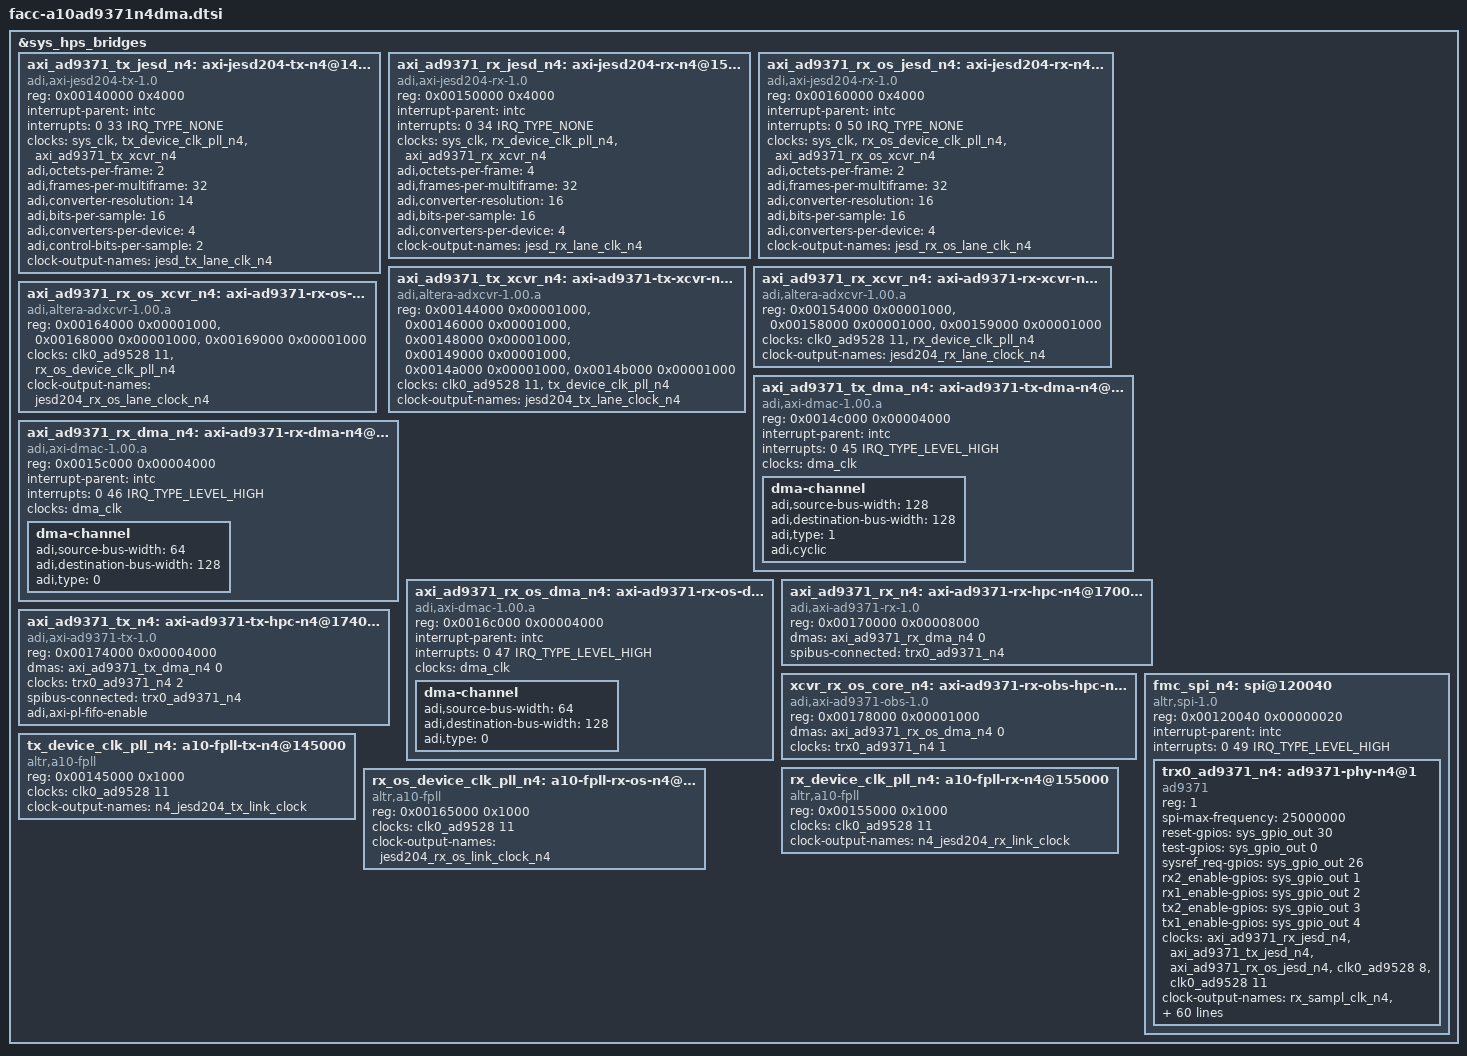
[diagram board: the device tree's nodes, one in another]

&sys_hps_bridges {
	axi_ad9371_tx_jesd_n4: axi-jesd204-tx-n4@140000 {
		compatible = "adi,axi-jesd204-tx-1.0";
		reg = <0x00140000 0x4000>;

		interrupt-parent = <&intc>;
		interrupts = <0 33 IRQ_TYPE_NONE>;

		clocks = <&sys_clk>, <&tx_device_clk_pll_n4>, <&axi_ad9371_tx_xcvr_n4>;
		clock-names = "s_axi_aclk", "device_clk", "lane_clk";

		adi,octets-per-frame = <2>;
		adi,frames-per-multiframe = <32>;
		adi,converter-resolution = <14>;
		adi,bits-per-sample = <16>;
		adi,converters-per-device = <4>;
		adi,control-bits-per-sample = <2>;

		#clock-cells = <0>;
		clock-output-names = "jesd_tx_lane_clk_n4";
	};

	axi_ad9371_rx_jesd_n4: axi-jesd204-rx-n4@150000 {
		compatible = "adi,axi-jesd204-rx-1.0";
		reg = <0x00150000 0x4000>;

		interrupt-parent = <&intc>;
		interrupts = <0 34 IRQ_TYPE_NONE>;

		clocks = <&sys_clk>, <&rx_device_clk_pll_n4>, <&axi_ad9371_rx_xcvr_n4>;
		clock-names = "s_axi_aclk", "device_clk", "lane_clk";

		adi,octets-per-frame = <4>;
		adi,frames-per-multiframe = <32>;
		adi,converter-resolution = <16>;
		adi,bits-per-sample = <16>;
		adi,converters-per-device = <4>;

		#clock-cells = <0>;
		clock-output-names = "jesd_rx_lane_clk_n4";
	};

	axi_ad9371_rx_os_jesd_n4: axi-jesd204-rx-n4@160000 {
		compatible = "adi,axi-jesd204-rx-1.0";
		reg = <0x00160000 0x4000>;

		interrupt-parent = <&intc>;
		interrupts = <0 50 IRQ_TYPE_NONE>;

		clocks = <&sys_clk>, <&rx_os_device_clk_pll_n4>, <&axi_ad9371_rx_os_xcvr_n4>;
		clock-names = "s_axi_aclk", "device_clk", "lane_clk";

		adi,octets-per-frame = <2>;
		adi,frames-per-multiframe = <32>;
		adi,converter-resolution = <16>;
		adi,bits-per-sample = <16>;
		adi,converters-per-device = <4>;

		#clock-cells = <0>;
		clock-output-names = "jesd_rx_os_lane_clk_n4";
	};

	 axi_ad9371_tx_xcvr_n4: axi-ad9371-tx-xcvr-n4@144000 {
		compatible = "adi,altera-adxcvr-1.00.a";
		reg = <0x00144000 0x00001000>,
			<0x00146000 0x00001000>,
			<0x00148000 0x00001000>,
			<0x00149000 0x00001000>,
			<0x0014a000 0x00001000>,
			<0x0014b000 0x00001000>;
		reg-names = "adxcvr", "atx-pll", "adxcfg-0", "adxcfg-1", "adxcfg-2", "adxcfg-3";

		clocks = <&clk0_ad9528 11>, <&tx_device_clk_pll_n4>;
		clock-names = "ref", "link";

		#clock-cells = <0>;
		clock-output-names = "jesd204_tx_lane_clock_n4";
	};

	axi_ad9371_rx_xcvr_n4: axi-ad9371-rx-xcvr-n4@154000 {
		compatible = "adi,altera-adxcvr-1.00.a";
		reg = <0x00154000 0x00001000>,
			<0x00158000 0x00001000>,
			<0x00159000 0x00001000>;
		reg-names = "adxcvr", "adxcfg-0", "adxcfg-1";

		clocks = <&clk0_ad9528 11>, <&rx_device_clk_pll_n4>;
		clock-names = "ref", "link";

		#clock-cells = <0>;
		clock-output-names = "jesd204_rx_lane_clock_n4";
	};

	axi_ad9371_rx_os_xcvr_n4: axi-ad9371-rx-os-xcvr-n4@164000 {
		compatible = "adi,altera-adxcvr-1.00.a";
		reg = <0x00164000 0x00001000>,
			<0x00168000 0x00001000>,
			<0x00169000 0x00001000>;
		reg-names = "adxcvr", "adxcfg-0", "adxcfg-1";

		clocks = <&clk0_ad9528 11>, <&rx_os_device_clk_pll_n4>;
		clock-names = "ref", "link";

		#clock-cells = <0>;
		clock-output-names = "jesd204_rx_os_lane_clock_n4";
	};

	axi_ad9371_tx_dma_n4: axi-ad9371-tx-dma-n4@14c000 {
		compatible = "adi,axi-dmac-1.00.a";
		reg = <0x0014c000 0x00004000>;
		interrupt-parent = <&intc>;
		interrupts = <0 45 IRQ_TYPE_LEVEL_HIGH>;
		#dma-cells = <1>;
		clocks = <&dma_clk>;

		dma-channel {
			adi,source-bus-width = <128>;
			adi,destination-bus-width = <128>;
			adi,type = <1>;
			adi,cyclic;
		};
	};

	axi_ad9371_rx_dma_n4: axi-ad9371-rx-dma-n4@15c000 {
		compatible = "adi,axi-dmac-1.00.a";
		reg = <0x0015c000 0x00004000>;
		interrupt-parent = <&intc>;
		interrupts = <0 46 IRQ_TYPE_LEVEL_HIGH>;
		#dma-cells = <1>;
		clocks = <&dma_clk>;

		dma-channel {
			adi,source-bus-width = <64>;
			adi,destination-bus-width = <128>;
			adi,type = <0>;
		};
	};

	axi_ad9371_rx_os_dma_n4: axi-ad9371-rx-os-dma-n4@16c000 {
		compatible = "adi,axi-dmac-1.00.a";
		reg = <0x0016c000 0x00004000>;
		interrupt-parent = <&intc>;
		interrupts = <0 47 IRQ_TYPE_LEVEL_HIGH>;
		#dma-cells = <1>;
		clocks = <&dma_clk>;

		dma-channel {
			adi,source-bus-width = <64>;
			adi,destination-bus-width = <128>;
			adi,type = <0>;
		};
	};

	axi_ad9371_rx_n4: axi-ad9371-rx-hpc-n4@170000 {
		compatible = "adi,axi-ad9371-rx-1.0";
		reg = <0x00170000 0x00008000>;
		dmas = <&axi_ad9371_rx_dma_n4 0>;
		dma-names = "rx";
		spibus-connected = <&trx0_ad9371_n4>;
	};

	axi_ad9371_tx_n4: axi-ad9371-tx-hpc-n4@174000 {
		compatible = "adi,axi-ad9371-tx-1.0";
		reg = <0x00174000 0x00004000>;
		dmas = <&axi_ad9371_tx_dma_n4 0>;
		dma-names = "tx";
		clocks = <&trx0_ad9371_n4 2>;
		clock-names = "sampl_clk";
		spibus-connected = <&trx0_ad9371_n4>;
		adi,axi-pl-fifo-enable;/* RxDMA fifo mode */
		//adi,axi-pl-fifo-disable;
	};

	xcvr_rx_os_core_n4: axi-ad9371-rx-obs-hpc-n4@178000 {
		compatible = "adi,axi-ad9371-obs-1.0";
		reg = <0x00178000 0x00001000>;
		dmas = <&axi_ad9371_rx_os_dma_n4 0>;
		dma-names = "rx";
		clocks = <&trx0_ad9371_n4 1>;
		clock-names = "sampl_clk";
	};

	tx_device_clk_pll_n4: a10-fpll-tx-n4@145000 {
		compatible = "altr,a10-fpll";
		reg = <0x00145000 0x1000>;
		clocks = <&clk0_ad9528 11>;

		#clock-cells = <0>;
		clock-output-names = "n4_jesd204_tx_link_clock";
	};

	rx_device_clk_pll_n4: a10-fpll-rx-n4@155000 {
		compatible = "altr,a10-fpll";
		reg = <0x00155000 0x1000>;
		clocks = <&clk0_ad9528 11>;

		#clock-cells = <0>;
		clock-output-names = "n4_jesd204_rx_link_clock";
	};

	rx_os_device_clk_pll_n4: a10-fpll-rx-os-n4@165000 {
		compatible = "altr,a10-fpll";
		reg = <0x00165000 0x1000>;
		clocks = <&clk0_ad9528 11>;

		#clock-cells = <0>;
		clock-output-names = "jesd204_rx_os_link_clock_n4";
	};

	fmc_spi_n4: spi@120040 {
		compatible = "altr,spi-1.0";
		reg = <0x00120040 0x00000020>;
		interrupt-parent = <&intc>;
		interrupts = <0 49 IRQ_TYPE_LEVEL_HIGH>;
		#address-cells = <0x1>;
		#size-cells = <0x0>;
	};
};

&fmc_spi_n4 {
	trx0_ad9371_n4: ad9371-phy-n4@1 {
		#address-cells = <1>;
		#size-cells = <0>;
		#clock-cells = <1>;
		compatible = "ad9371";

		/* SPI Setup */
		reg = <1>;
		spi-max-frequency = <25000000>;

		reset-gpios = <&sys_gpio_out 30 0>;
		test-gpios = <&sys_gpio_out 0 0>;
		sysref_req-gpios = <&sys_gpio_out 26 0>;
		rx2_enable-gpios = <&sys_gpio_out 1 0>;
		rx1_enable-gpios = <&sys_gpio_out 2 0>;
		tx2_enable-gpios = <&sys_gpio_out 3 0>;
		tx1_enable-gpios = <&sys_gpio_out 4 0>;

		/* all interrupts in HW design should be reviewed */
		//interrupt-parent = <&intc>;
		//interrupts = <0 49 IRQ_TYPE_LEVEL_HIGH>;

		/* Clocks */
		clocks = <&axi_ad9371_rx_jesd_n4>, <&axi_ad9371_tx_jesd_n4>,
			<&axi_ad9371_rx_os_jesd_n4>, <&clk0_ad9528 8>,
			<&clk0_ad9528 11>;
		clock-names = "jesd_rx_clk", "jesd_tx_clk",
			"jesd_rx_os_clk", "dev_clk", "fmc_clk";
		clock-output-names = "rx_sampl_clk_n4", "rx_os_sampl_clk_n4", "tx_sampl_clk_n4";

		adi,clocks-clk-pll-vco-freq_khz = <9830400>;
		adi,clocks-device-clock_khz = <122880>;
		adi,clocks-clk-pll-hs-div = <4>;
		adi,clocks-clk-pll-vco-div = <2>;

		adi,jesd204-obs-framer-over-sample = <0>;

		adi,rx-profile-adc-div = <1>;
		adi,rx-profile-en-high-rej-dec5 = <1>;
		adi,rx-profile-iq-rate_khz = <122880>;
		adi,rx-profile-rf-bandwidth_hz = <100000000>;
		adi,rx-profile-rhb1-decimation = <1>;
		adi,rx-profile-rx-bbf-3db-corner_khz = <100000>;
		adi,rx-profile-rx-dec5-decimation = <5>;
		adi,rx-profile-rx-fir-decimation = <2>;

		adi,rx-profile-rx-fir-gain_db = <(-6)>;
		adi,rx-profile-rx-fir-num-fir-coefs = <48>;
		adi,rx-profile-rx-fir-coefs = /bits/ 16 <(-5) (-26) (32) (51) (-67) (-116) (140) (212) (-252) (-367) (429) (595) (-688) (-931) (1072) (1427) (-1650) (-2188) (2612) (3496) (-4802) (-7591) (9656) (32317) (32317) (9656) (-7591) (-4802) (3496) (2612) (-2188) (-1650) (1427) (1072) (-931) (-688) (595) (429) (-367) (-252) (212) (140) (-116) (-67) (51) (32) (-26) (-5)>;

		adi,rx-profile-custom-adc-profile = /bits/ 16  <534 386 201 98 1280 491 1591 279 1306 104 792 28 48 39 23 187>;

		adi,obs-profile-adc-div = <1>;
		adi,obs-profile-en-high-rej-dec5 = <1>;
		adi,obs-profile-iq-rate_khz = <245760>;
		adi,obs-profile-rf-bandwidth_hz = <200000000>;
		adi,obs-profile-rhb1-decimation = <1>;
		adi,obs-profile-rx-bbf-3db-corner_khz = <100000>;
		adi,obs-profile-rx-dec5-decimation = <5>;
		adi,obs-profile-rx-fir-decimation = <1>;

		adi,obs-profile-rx-fir-gain_db = <6>;
		adi,obs-profile-rx-fir-num-fir-coefs = <24>;
		adi,obs-profile-rx-fir-coefs = /bits/ 16 <(-289) (81) (-23) (-86) (229) (-354) (397) (-233) (-657) (1699) (-4172) (23010) (-4172) (1699) (-657) (-233) (397) (-354) (229) (-86) (-23) (81) (-289) (0)>;

		adi,obs-profile-custom-adc-profile = /bits/ 16  <450 349 201 98 1280 730 1626 818 1476 732 834 20 41 36 24 200>;
		adi,obs-settings-custom-loopback-adc-profile = /bits/ 16  <569 369 201 98 1280 291 1541 149 1320 58 807 34 48 40 23 189>;

		adi,tx-profile-dac-div = <1>;
		adi,tx-profile-iq-rate_khz = <245760>;
		adi,tx-profile-primary-sig-bandwidth_hz = <75000000>;
		adi,tx-profile-rf-bandwidth_hz = <200000000>;
		adi,tx-profile-thb1-interpolation = <2>;
		adi,tx-profile-thb2-interpolation = <1>;
		adi,tx-profile-tx-bbf-3db-corner_khz = <100000>;
		adi,tx-profile-tx-dac-3db-corner_khz = <187000>;
		adi,tx-profile-tx-fir-interpolation = <1>;
		adi,tx-profile-tx-input-hb-interpolation = <1>;

		adi,tx-profile-tx-fir-gain_db = <6>;
		adi,tx-profile-tx-fir-num-fir-coefs = <16>;
		adi,tx-profile-tx-fir-coefs = /bits/ 16 <(6) (-270) (203) (-168) (-84) (983) (-3222) (21143) (-3222) (983) (-84) (-168) (203) (-270) (6) (0)>;

		adi,sniffer-profile-adc-div = <1>;
		adi,sniffer-profile-en-high-rej-dec5 = <0>;
		adi,sniffer-profile-iq-rate_khz = <30720>;
		adi,sniffer-profile-rf-bandwidth_hz = <20000000>;
		adi,sniffer-profile-rhb1-decimation = <2>;
		adi,sniffer-profile-rx-bbf-3db-corner_khz = <100000>;
		adi,sniffer-profile-rx-dec5-decimation = <5>;
		adi,sniffer-profile-rx-fir-decimation = <4>;
#if 0
		/* Jacky:2018/07/25: enable pin-mode 
		   https://wiki.analog.com/resources/tools-software/linux-drivers/iio-transceiver/ad9371-customization */
		adi,arm-gpio-use-rx2-enable-pin = <1>;	// 0= RX1_ENABLE controls RX1&RX2, 1= separate RX1/RX2_ENABLE pins
		adi,arm-gpio-use-tx2-enable-pin = <1>;	// 0= TX1_ENABLE controls TX1&TX2, 1= separate TX1/TX2_ENABLE pins
		adi,arm-gpio-tx-rx-pin-mode = <1>;		// 0= ARM command mode, 1 = Pin mode to power up Tx/Rx chains
		adi,arm-gpio-orx-pin-mode = <1>;		// 0= ARM command mode, 1 = Pin mode to power up ObsRx receiver
		// to be tested: enable pin-mode but NOT enable gpio-ack
		adi,arm-gpio-orx-trigger-pin = <0>;		// Select desired GPIO pin (valid 4-15)
		adi,arm-gpio-orx-mode2-pin = <0>;		// Select desired GPIO pin (valid 0-18)
		adi,arm-gpio-orx-mode1-pin = <0>;		// Select desired GPIO pin (valid 0-18)
		adi,arm-gpio-orx-mode0-pin = <0>;		// Select desired GPIO pin (valid 0-18)
		adi,arm-gpio-rx1-enable-ack = <0>;		// Select desired GPIO pin (0-15), [4] = Output Enable
		adi,arm-gpio-rx2-enable-ack = <0>;		// Select desired GPIO pin (0-15), [4] = Output Enable
		adi,arm-gpio-tx1-enable-ack = <0>;		// Select desired GPIO pin (0-15), [4] = Output Enable
		adi,arm-gpio-tx2-enable-ack = <0>;		// Select desired GPIO pin (0-15), [4] = Output Enable
		adi,arm-gpio-orx1-enable-ack = <0>;		// Select desired GPIO pin (0-15), [4] = Output Enable
		adi,arm-gpio-orx2-enable-ack = <0>;		// Select desired GPIO pin (0-15), [4] = Output Enable
		adi,arm-gpio-srx-enable-ack = <0>;		// Select desired GPIO pin (0-15), [4] = Output Enable
		adi,arm-gpio-tx-obs-select = <0>;		// Select desired GPIO pin (0-15), [4] = Output Enable.
			// When 2 Tx are used with only 1 ORx input, this GPIO tells BBIC which Tx channel is active
			// for calibrations, so BBIC can route correct RF Tx path into the single ORx input
		adi,arm-gpio-enable-mask = <0>;
#endif
	};
};

